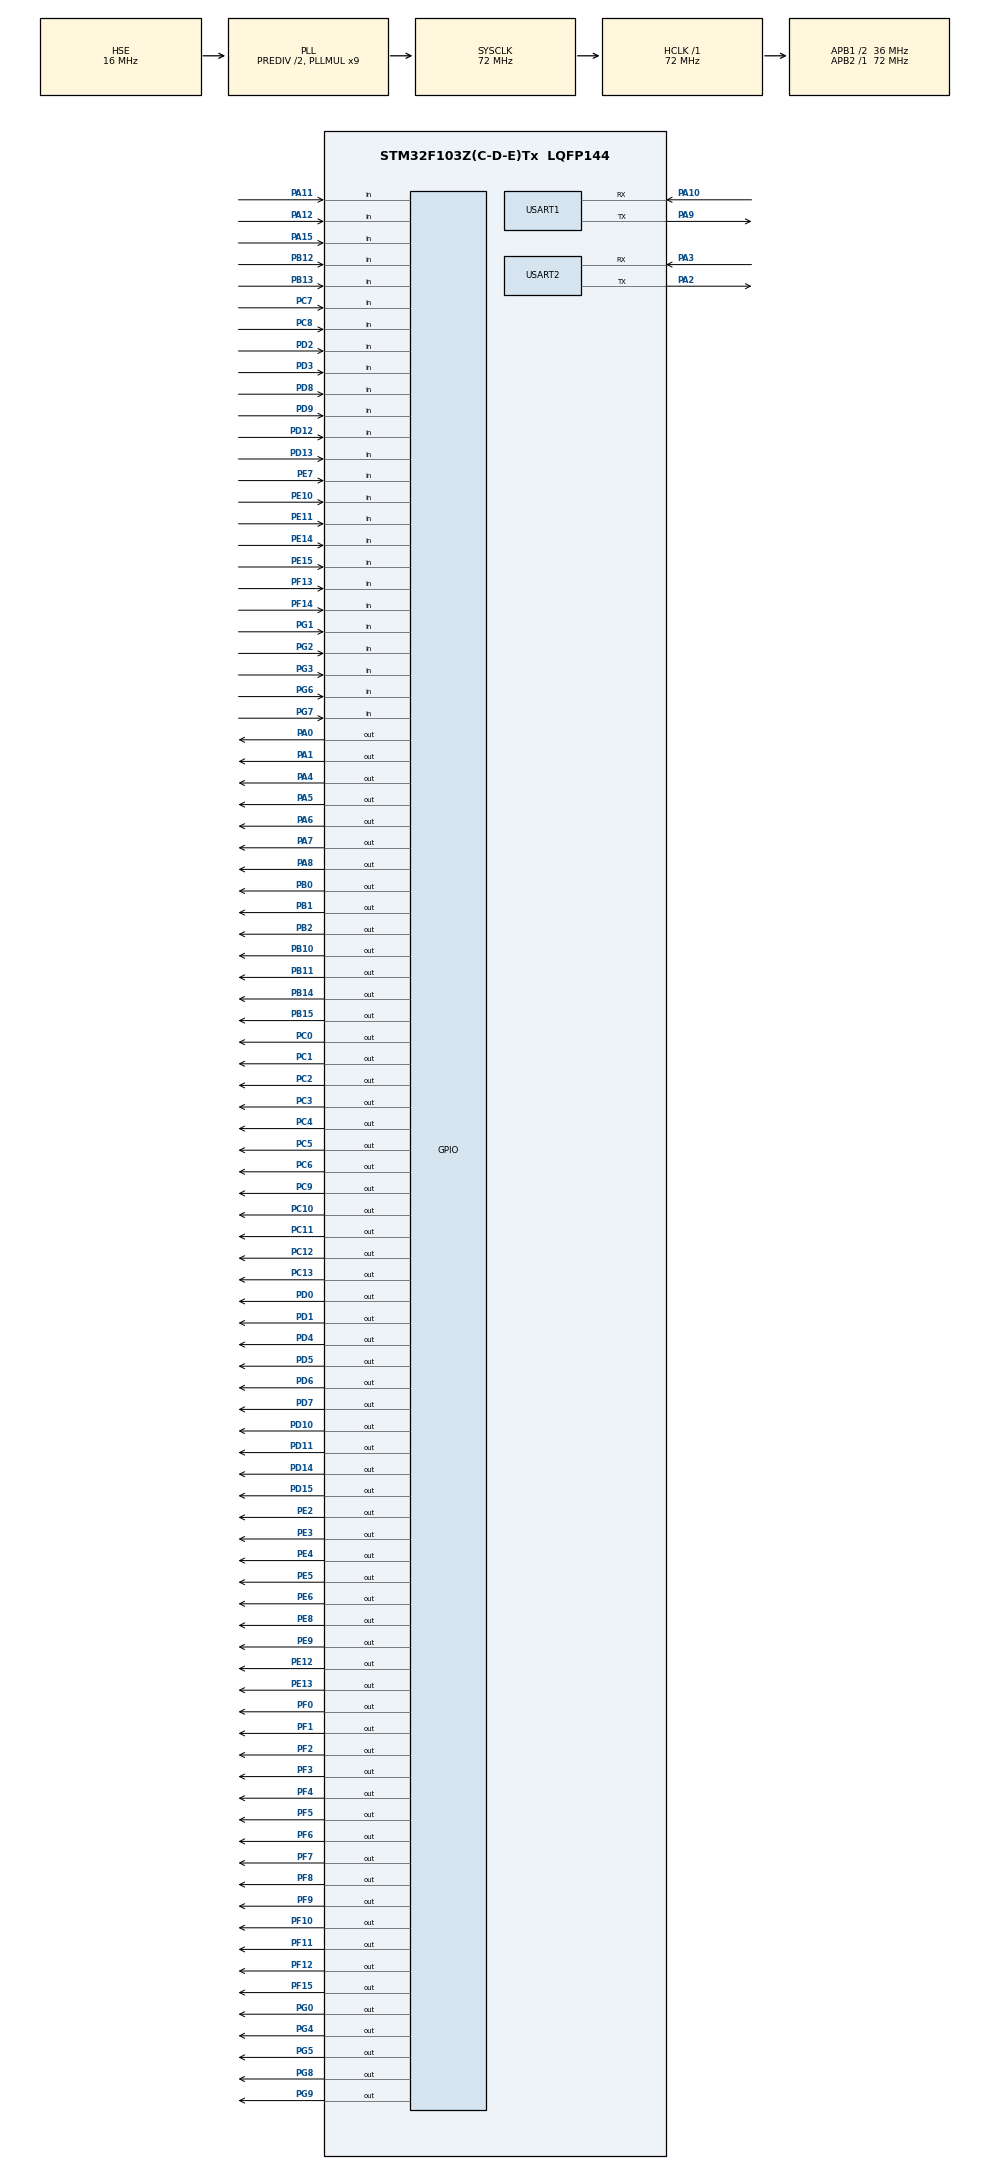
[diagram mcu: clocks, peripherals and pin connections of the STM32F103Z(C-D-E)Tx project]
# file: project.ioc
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Dma.Request0=USART2_RX
Dma.Request1=USART2_TX
Dma.Request2=USART1_TX
Dma.USART1_TX.2.Direction=DMA_MEMORY_TO_PERIPH
Dma.USART1_TX.2.Instance=DMA1_Channel4
Dma.USART1_TX.2.MemDataAlignment=DMA_MDATAALIGN_BYTE
Dma.USART1_TX.2.MemInc=DMA_MINC_ENABLE
Dma.USART1_TX.2.Mode=DMA_NORMAL
Dma.USART1_TX.2.PeriphDataAlignment=DMA_PDATAALIGN_BYTE
Dma.USART1_TX.2.PeriphInc=DMA_PINC_DISABLE
Dma.USART1_TX.2.Priority=DMA_PRIORITY_LOW
Dma.USART2_RX.0.Direction=DMA_PERIPH_TO_MEMORY
Dma.USART2_RX.0.Instance=DMA1_Channel6
Dma.USART2_RX.0.MemDataAlignment=DMA_MDATAALIGN_BYTE
Dma.USART2_RX.0.MemInc=DMA_MINC_ENABLE
Dma.USART2_RX.0.Mode=DMA_NORMAL
Dma.USART2_RX.0.PeriphDataAlignment=DMA_PDATAALIGN_BYTE
Dma.USART2_RX.0.PeriphInc=DMA_PINC_DISABLE
Dma.USART2_RX.0.Priority=DMA_PRIORITY_LOW
Dma.USART2_TX.1.Direction=DMA_MEMORY_TO_PERIPH
Dma.USART2_TX.1.Instance=DMA1_Channel7
Dma.USART2_TX.1.MemDataAlignment=DMA_MDATAALIGN_BYTE
Dma.USART2_TX.1.MemInc=DMA_MINC_ENABLE
Dma.USART2_TX.1.Mode=DMA_NORMAL
Dma.USART2_TX.1.PeriphDataAlignment=DMA_PDATAALIGN_BYTE
Dma.USART2_TX.1.PeriphInc=DMA_PINC_DISABLE
Dma.USART2_TX.1.Priority=DMA_PRIORITY_LOW
FREERTOS.Tasks01=defaultTask,0,128,StartDefaultTask,Default,NULL,Dynamic,NULL,NULL
IWDG.Prescaler=IWDG_PRESCALER_256
Mcu.Family=STM32F1
Mcu.Name=STM32F103Z(C-D-E)Tx
Mcu.Package=LQFP144
NVIC.DMA1_Channel4_IRQn=true\:5\:0\:false\:false\:true\:true\:false
NVIC.DMA1_Channel6_IRQn=true\:5\:0\:false\:false\:true\:true\:false
NVIC.DMA1_Channel7_IRQn=true\:5\:0\:false\:false\:true\:true\:false
NVIC.PriorityGroup=NVIC_PRIORITYGROUP_4
NVIC.USART1_IRQn=true\:5\:0\:false\:false\:true\:true\:true
NVIC.USART2_IRQn=true\:5\:0\:false\:false\:true\:true\:true
OSC_IN.Mode=HSE-External-Oscillator
OSC_IN.Signal=RCC_OSC_IN
OSC_OUT.Mode=HSE-External-Oscillator
OSC_OUT.Signal=RCC_OSC_OUT
PA0-WKUP.Signal=GPIO_Output
PA1.Signal=GPIO_Output
PA10.Mode=Asynchronous
PA10.Signal=USART1_RX
PA11.GPIO_PuPd=GPIO_PULLUP
PA11.Signal=GPIO_Input
PA12.GPIO_PuPd=GPIO_PULLUP
PA12.Signal=GPIO_Input
PA13.Mode=Serial_Wire
PA13.Signal=SYS_JTMS-SWDIO
PA14.Mode=Serial_Wire
PA14.Signal=SYS_JTCK-SWCLK
PA15.Signal=GPIO_Input
PA2.Mode=Asynchronous
PA2.Signal=USART2_TX
PA3.Mode=Asynchronous
PA3.Signal=USART2_RX
PA4.Signal=GPIO_Output
PA5.Signal=GPIO_Output
PA6.Signal=GPIO_Output
PA7.Signal=GPIO_Output
PA8.Signal=GPIO_Output
PA9.Mode=Asynchronous
PA9.Signal=USART1_TX
PB0.Signal=GPIO_Output
PB1.Signal=GPIO_Output
PB10.Signal=GPIO_Output
PB11.Signal=GPIO_Output
PB12.GPIO_PuPd=GPIO_PULLUP
PB12.Signal=GPIO_Input
PB13.GPIO_PuPd=GPIO_PULLUP
PB13.Signal=GPIO_Input
PB14.Signal=GPIO_Output
PB15.Signal=GPIO_Output
PB2.Signal=GPIO_Output
PC0.Signal=GPIO_Output
PC1.Signal=GPIO_Output
PC10.Signal=GPIO_Output
PC11.Signal=GPIO_Output
PC12.Signal=GPIO_Output
PC13-TAMPER-RTC.Signal=GPIO_Output
PC14-OSC32_IN.Mode=LSE-External-Oscillator
PC14-OSC32_IN.Signal=RCC_OSC32_IN
PC15-OSC32_OUT.Mode=LSE-External-Oscillator
PC15-OSC32_OUT.Signal=RCC_OSC32_OUT
PC2.Signal=GPIO_Output
PC3.Signal=GPIO_Output
PC4.Signal=GPIO_Output
PC5.Signal=GPIO_Output
PC6.Signal=GPIO_Output
PC7.GPIO_PuPd=GPIO_PULLUP
PC7.Signal=GPIO_Input
PC8.GPIO_PuPd=GPIO_PULLUP
PC8.Signal=GPIO_Input
PC9.Signal=GPIO_Output
PD0.Signal=GPIO_Output
PD1.Signal=GPIO_Output
PD10.Signal=GPIO_Output
PD11.Signal=GPIO_Output
PD12.GPIO_PuPd=GPIO_PULLUP
PD12.Signal=GPIO_Input
PD13.GPIO_PuPd=GPIO_PULLUP
PD13.Signal=GPIO_Input
PD14.Signal=GPIO_Output
PD15.Signal=GPIO_Output
PD2.GPIO_PuPd=GPIO_PULLUP
PD2.Signal=GPIO_Input
PD3.GPIO_PuPd=GPIO_NOPULL
PD3.Signal=GPIO_Input
PD4.Signal=GPIO_Output
PD5.Signal=GPIO_Output
PD6.Signal=GPIO_Output
PD7.Signal=GPIO_Output
PD8.GPIO_PuPd=GPIO_PULLUP
PD8.Signal=GPIO_Input
PD9.GPIO_PuPd=GPIO_PULLUP
PD9.Signal=GPIO_Input
PE10.GPIO_PuPd=GPIO_PULLUP
PE10.Signal=GPIO_Input
PE11.GPIO_PuPd=GPIO_PULLUP
PE11.Signal=GPIO_Input
PE12.Signal=GPIO_Output
PE13.Signal=GPIO_Output
PE14.GPIO_PuPd=GPIO_PULLUP
PE14.Signal=GPIO_Input
PE15.GPIO_PuPd=GPIO_PULLUP
PE15.Signal=GPIO_Input
PE2.Signal=GPIO_Output
PE3.Signal=GPIO_Output
PE4.Signal=GPIO_Output
PE5.Signal=GPIO_Output
PE6.Signal=GPIO_Output
PE7.GPIO_PuPd=GPIO_PULLUP
PE7.Signal=GPIO_Input
PE8.Signal=GPIO_Output
PE9.Signal=GPIO_Output
PF0.Signal=GPIO_Output
PF1.Signal=GPIO_Output
PF10.Signal=GPIO_Output
PF11.Signal=GPIO_Output
PF12.Signal=GPIO_Output
PF13.GPIO_PuPd=GPIO_PULLUP
PF13.Signal=GPIO_Input
PF14.GPIO_PuPd=GPIO_PULLUP
PF14.Signal=GPIO_Input
PF15.Signal=GPIO_Output
PF2.Signal=GPIO_Output
PF3.Signal=GPIO_Output
PF4.Signal=GPIO_Output
PF5.Signal=GPIO_Output
PF6.Signal=GPIO_Output
PF7.Signal=GPIO_Output
PF8.Signal=GPIO_Output
PF9.Signal=GPIO_Output
PG0.Signal=GPIO_Output
PG1.GPIO_PuPd=GPIO_PULLUP
PG1.Signal=GPIO_Input
PG2.GPIO_PuPd=GPIO_PULLUP
PG2.Signal=GPIO_Input
PG3.GPIO_PuPd=GPIO_PULLUP
PG3.Signal=GPIO_Input
PG4.Signal=GPIO_Output
PG5.Signal=GPIO_Output
PG6.GPIO_PuPd=GPIO_PULLUP
PG6.Signal=GPIO_Input
PG7.GPIO_PuPd=GPIO_PULLUP
PG7.Signal=GPIO_Input
PG8.Signal=GPIO_Output
PG9.Signal=GPIO_Output
ProjectManager.HeapSize=0x200
ProjectManager.StackSize=0x400
ProjectManager.TargetToolchain=EWARM V8
RCC.AHBFreq_Value=72000000
RCC.APB1CLKDivider=RCC_HCLK_DIV2
RCC.APB1Freq_Value=36000000
RCC.APB1TimFreq_Value=72000000
RCC.APB2Freq_Value=72000000
RCC.APB2TimFreq_Value=72000000
RCC.HCLKFreq_Value=72000000
RCC.HSEDivPLL=RCC_HSE_PREDIV_DIV2
RCC.HSE_VALUE=16000000
RCC.PLLMUL=RCC_PLL_MUL9
RCC.PLLSourceVirtual=RCC_PLLSOURCE_HSE
RCC.RTCClockSelection=RCC_RTCCLKSOURCE_LSE
RCC.SYSCLKFreq_VALUE=72000000
RCC.SYSCLKSource=RCC_SYSCLKSOURCE_PLLCLK
RCC.USBFreq_Value=72000000
USART1.VirtualMode=VM_ASYNC
USART2.VirtualMode=VM_ASYNC
VP_FREERTOS_VS_ENABLE.Mode=Enabled
VP_IWDG_VS_IWDG.Mode=IWDG_Activate
board=custom

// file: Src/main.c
/**
  ******************************************************************************
  * @file           : main.c
  * @brief          : Main program body
  ******************************************************************************
  * This notice applies to any and all portions of this file
  * that are not between comment pairs USER CODE BEGIN and
  * USER CODE END. Other portions of this file, whether
  * inserted by the user or by software development tools
  * are owned by their respective copyright owners.
  *
  * Copyright (c) 2019 STMicroelectronics International N.V.
  * All rights reserved.
  *
  * Redistribution and use in source and binary forms, with or without
  * modification, are permitted, provided that the following conditions are met:
  *
  * 1. Redistribution of source code must retain the above copyright notice,
  *    this list of conditions and the following disclaimer.
  * 2. Redistributions in binary form must reproduce the above copyright notice,
  *    this list of conditions and the following disclaimer in the documentation
  *    and/or other materials provided with the distribution.
  * 3. Neither the name of STMicroelectronics nor the names of other
  *    contributors to this software may be used to endorse or promote products
  *    derived from this software without specific written permission.
  * 4. This software, including modifications and/or derivative works of this
  *    software, must execute solely and exclusively on microcontroller or
  *    microprocessor devices manufactured by or for STMicroelectronics.
  * 5. Redistribution and use of this software other than as permitted under
  *    this license is void and will automatically terminate your rights under
  *    this license.
  *
  * THIS SOFTWARE IS PROVIDED BY STMICROELECTRONICS AND CONTRIBUTORS "AS IS"
  * AND ANY EXPRESS, IMPLIED OR STATUTORY WARRANTIES, INCLUDING, BUT NOT
  * LIMITED TO, THE IMPLIED WARRANTIES OF MERCHANTABILITY, FITNESS FOR A
  * PARTICULAR PURPOSE AND NON-INFRINGEMENT OF THIRD PARTY INTELLECTUAL PROPERTY
  * RIGHTS ARE DISCLAIMED TO THE FULLEST EXTENT PERMITTED BY LAW. IN NO EVENT
  * SHALL STMICROELECTRONICS OR CONTRIBUTORS BE LIABLE FOR ANY DIRECT, INDIRECT,
  * INCIDENTAL, SPECIAL, EXEMPLARY, OR CONSEQUENTIAL DAMAGES (INCLUDING, BUT NOT
  * LIMITED TO, PROCUREMENT OF SUBSTITUTE GOODS OR SERVICES; LOSS OF USE, DATA,
  * OR PROFITS; OR BUSINESS INTERRUPTION) HOWEVER CAUSED AND ON ANY THEORY OF
  * LIABILITY, WHETHER IN CONTRACT, STRICT LIABILITY, OR TORT (INCLUDING
  * NEGLIGENCE OR OTHERWISE) ARISING IN ANY WAY OUT OF THE USE OF THIS SOFTWARE,
  * EVEN IF ADVISED OF THE POSSIBILITY OF SUCH DAMAGE.
  *
  ******************************************************************************
  */
#include "main.h"
#include "stm32f1xx_hal.h"
#include "cmsis_os.h"

/* USER CODE BEGIN Includes */
#include "user_comm.h"
/* USER CODE END Includes */

IWDG_HandleTypeDef hiwdg;

UART_HandleTypeDef huart1;
UART_HandleTypeDef huart2;
DMA_HandleTypeDef hdma_usart1_tx;
DMA_HandleTypeDef hdma_usart2_rx;
DMA_HandleTypeDef hdma_usart2_tx;

osThreadId defaultTaskHandle;

/* USER CODE BEGIN PV */
/* Private variables ---------------------------------------------------------*/

/* USER CODE END PV */

void SystemClock_Config(void);
static void MX_GPIO_Init(void);
static void MX_DMA_Init(void);
static void MX_USART1_UART_Init(void);
static void MX_USART2_UART_Init(void);
static void MX_IWDG_Init(void);
void StartDefaultTask(void const * argument);

/* USER CODE BEGIN PFP */
/* Private function prototypes -----------------------------------------------*/

/* USER CODE END PFP */

/* USER CODE BEGIN 0 */
#ifdef __GNUC__
  /* With GCC/RAISONANCE, small printf (option LD Linker->Libraries->Small printf
     set to 'Yes') calls __io_putchar() */
  #define PUTCHAR_PROTOTYPE int __io_putchar(int ch)
#else
  #define PUTCHAR_PROTOTYPE int fputc(int ch, FILE *f)
#endif /* __GNUC__ */
/**
  * @brief  Retargets the C library printf function to the USART.
  * @param  None
  * @retval None
  */
PUTCHAR_PROTOTYPE
{
  /* Place your implementation of fputc here */
  /* e.g. write a character to the EVAL_COM1 and Loop until the end of transmission */
  HAL_UART_Transmit(&huart1, (uint8_t *)&ch, 1, 0xFFFF);

  return ch;
}

/* USER CODE END 0 */

int main(void)
{

  /* MCU Configuration----------------------------------------------------------*/

  /* Reset of all peripherals, Initializes the Flash interface and the Systick. */
  HAL_Init();

  /* Configure the system clock */
  SystemClock_Config();

  /* Initialize all configured peripherals */
  MX_GPIO_Init();
  MX_DMA_Init();
  MX_USART1_UART_Init();
  MX_USART2_UART_Init();
  MX_IWDG_Init();
  /* USER CODE BEGIN 2 */
  printf("main init printf ok \n");

  /* USER CODE END 2 */

  /* Create the thread(s) */
  /* definition and creation of defaultTask */
  osThreadDef(defaultTask, StartDefaultTask, osPriorityNormal, 0, 128);
  defaultTaskHandle = osThreadCreate(osThread(defaultTask), NULL);

  /* Start scheduler */
  osKernelStart();

  /* We should never get here as control is now taken by the scheduler */

  /* Infinite loop */
  while (1)
  {

  }

}

void SystemClock_Config(void)
{

  RCC_OscInitTypeDef RCC_OscInitStruct;
  RCC_ClkInitTypeDef RCC_ClkInitStruct;

    /**Initializes the CPU, AHB and APB busses clocks
    */
  RCC_OscInitStruct.OscillatorType = RCC_OSCILLATORTYPE_LSI|RCC_OSCILLATORTYPE_HSE;
  RCC_OscInitStruct.HSEState = RCC_HSE_ON;
  RCC_OscInitStruct.HSEPredivValue = RCC_HSE_PREDIV_DIV2;
  RCC_OscInitStruct.HSIState = RCC_HSI_ON;
  RCC_OscInitStruct.LSIState = RCC_LSI_ON;
  RCC_OscInitStruct.PLL.PLLState = RCC_PLL_ON;
  RCC_OscInitStruct.PLL.PLLSource = RCC_PLLSOURCE_HSE;
  RCC_OscInitStruct.PLL.PLLMUL = RCC_PLL_MUL9;
  if (HAL_RCC_OscConfig(&RCC_OscInitStruct) != HAL_OK)
  {
    _Error_Handler(__FILE__, __LINE__);
  }

    /**Initializes the CPU, AHB and APB busses clocks
    */
  RCC_ClkInitStruct.ClockType = RCC_CLOCKTYPE_HCLK|RCC_CLOCKTYPE_SYSCLK
                              |RCC_CLOCKTYPE_PCLK1|RCC_CLOCKTYPE_PCLK2;
  RCC_ClkInitStruct.SYSCLKSource = RCC_SYSCLKSOURCE_PLLCLK;
  RCC_ClkInitStruct.AHBCLKDivider = RCC_SYSCLK_DIV1;
  RCC_ClkInitStruct.APB1CLKDivider = RCC_HCLK_DIV2;
  RCC_ClkInitStruct.APB2CLKDivider = RCC_HCLK_DIV1;

  if (HAL_RCC_ClockConfig(&RCC_ClkInitStruct, FLASH_LATENCY_2) != HAL_OK)
  {
    _Error_Handler(__FILE__, __LINE__);
  }

    /**Configure the Systick interrupt time
    */
  HAL_SYSTICK_Config(HAL_RCC_GetHCLKFreq()/1000);

    /**Configure the Systick
    */
  HAL_SYSTICK_CLKSourceConfig(SYSTICK_CLKSOURCE_HCLK);

  /* SysTick_IRQn interrupt configuration */
  HAL_NVIC_SetPriority(SysTick_IRQn, 15, 0);
}

/* IWDG init function */
static void MX_IWDG_Init(void)
{

  hiwdg.Instance = IWDG;
  hiwdg.Init.Prescaler = IWDG_PRESCALER_256;
  hiwdg.Init.Reload = 4095;
  if (HAL_IWDG_Init(&hiwdg) != HAL_OK)
  {
    _Error_Handler(__FILE__, __LINE__);
  }

}

/* USART1 init function */
static void MX_USART1_UART_Init(void)
{

  huart1.Instance = USART1;
  huart1.Init.BaudRate = 115200;
  huart1.Init.WordLength = UART_WORDLENGTH_8B;
  huart1.Init.StopBits = UART_STOPBITS_1;
  huart1.Init.Parity = UART_PARITY_NONE;
  huart1.Init.Mode = UART_MODE_TX_RX;
  huart1.Init.HwFlowCtl = UART_HWCONTROL_NONE;
  huart1.Init.OverSampling = UART_OVERSAMPLING_16;
  if (HAL_UART_Init(&huart1) != HAL_OK)
  {
    _Error_Handler(__FILE__, __LINE__);
  }

}

/* USART2 init function */
static void MX_USART2_UART_Init(void)
{

  huart2.Instance = USART2;
  huart2.Init.BaudRate = 115200;
  huart2.Init.WordLength = UART_WORDLENGTH_8B;
  huart2.Init.StopBits = UART_STOPBITS_1;
  huart2.Init.Parity = UART_PARITY_NONE;
  huart2.Init.Mode = UART_MODE_TX_RX;
  huart2.Init.HwFlowCtl = UART_HWCONTROL_NONE;
  huart2.Init.OverSampling = UART_OVERSAMPLING_16;
  if (HAL_UART_Init(&huart2) != HAL_OK)
  {
    _Error_Handler(__FILE__, __LINE__);
  }

}

static void MX_DMA_Init(void)
{
  /* DMA controller clock enable */
  __HAL_RCC_DMA1_CLK_ENABLE();

  /* DMA interrupt init */
  /* DMA1_Channel4_IRQn interrupt configuration */
  HAL_NVIC_SetPriority(DMA1_Channel4_IRQn, 5, 0);
  HAL_NVIC_EnableIRQ(DMA1_Channel4_IRQn);
  /* DMA1_Channel6_IRQn interrupt configuration */
  HAL_NVIC_SetPriority(DMA1_Channel6_IRQn, 5, 0);
  HAL_NVIC_EnableIRQ(DMA1_Channel6_IRQn);
  /* DMA1_Channel7_IRQn interrupt configuration */
  HAL_NVIC_SetPriority(DMA1_Channel7_IRQn, 5, 0);
  HAL_NVIC_EnableIRQ(DMA1_Channel7_IRQn);

}

/** Configure pins as
        * Analog
        * Input
        * Output
        * EVENT_OUT
        * EXTI
*/
static void MX_GPIO_Init(void)
{

  GPIO_InitTypeDef GPIO_InitStruct;

  /* GPIO Ports Clock Enable */
  __HAL_RCC_GPIOE_CLK_ENABLE();
  __HAL_RCC_GPIOC_CLK_ENABLE();
  __HAL_RCC_GPIOF_CLK_ENABLE();
  __HAL_RCC_GPIOA_CLK_ENABLE();
  __HAL_RCC_GPIOB_CLK_ENABLE();
  __HAL_RCC_GPIOG_CLK_ENABLE();
  __HAL_RCC_GPIOD_CLK_ENABLE();

  /*Configure GPIO pin Output Level */
  HAL_GPIO_WritePin(GPIOE, GPIO_PIN_2|GPIO_PIN_3|GPIO_PIN_4|GPIO_PIN_5
                          |GPIO_PIN_6|GPIO_PIN_8|GPIO_PIN_9|GPIO_PIN_12
                          |GPIO_PIN_13, GPIO_PIN_RESET);

  /*Configure GPIO pin Output Level */
  HAL_GPIO_WritePin(GPIOC, GPIO_PIN_13|GPIO_PIN_0|GPIO_PIN_1|GPIO_PIN_2
                          |GPIO_PIN_3|GPIO_PIN_4|GPIO_PIN_5|GPIO_PIN_6
                          |GPIO_PIN_9|GPIO_PIN_10|GPIO_PIN_11|GPIO_PIN_12, GPIO_PIN_RESET);

  /*Configure GPIO pin Output Level */
  HAL_GPIO_WritePin(GPIOF, GPIO_PIN_0|GPIO_PIN_1|GPIO_PIN_2|GPIO_PIN_3
                          |GPIO_PIN_4|GPIO_PIN_5|GPIO_PIN_6|GPIO_PIN_7
                          |GPIO_PIN_8|GPIO_PIN_9|GPIO_PIN_10|GPIO_PIN_11
                          |GPIO_PIN_12|GPIO_PIN_15, GPIO_PIN_RESET);

  /*Configure GPIO pin Output Level */
  HAL_GPIO_WritePin(GPIOA, GPIO_PIN_0|GPIO_PIN_1|GPIO_PIN_4|GPIO_PIN_5
                          |GPIO_PIN_6|GPIO_PIN_7|GPIO_PIN_8, GPIO_PIN_RESET);

  /*Configure GPIO pin Output Level */
  HAL_GPIO_WritePin(GPIOB, GPIO_PIN_0|GPIO_PIN_1|GPIO_PIN_2|GPIO_PIN_10
                          |GPIO_PIN_11|GPIO_PIN_14|GPIO_PIN_15, GPIO_PIN_RESET);

  /*Configure GPIO pin Output Level */
  HAL_GPIO_WritePin(GPIOG, GPIO_PIN_0|GPIO_PIN_4|GPIO_PIN_5|GPIO_PIN_8
                          |GPIO_PIN_9, GPIO_PIN_RESET);

  /*Configure GPIO pin Output Level */
  HAL_GPIO_WritePin(GPIOD, GPIO_PIN_10|GPIO_PIN_11|GPIO_PIN_14|GPIO_PIN_15
                          |GPIO_PIN_0|GPIO_PIN_1|GPIO_PIN_4|GPIO_PIN_5
                          |GPIO_PIN_6|GPIO_PIN_7, GPIO_PIN_RESET);

  /*Configure GPIO pins : PE2 PE3 PE4 PE5
                           PE6 PE8 PE9 PE12
                           PE13 */
  GPIO_InitStruct.Pin = GPIO_PIN_2|GPIO_PIN_3|GPIO_PIN_4|GPIO_PIN_5
                          |GPIO_PIN_6|GPIO_PIN_8|GPIO_PIN_9|GPIO_PIN_12
                          |GPIO_PIN_13;
  GPIO_InitStruct.Mode = GPIO_MODE_OUTPUT_PP;
  GPIO_InitStruct.Pull = GPIO_NOPULL;
  GPIO_InitStruct.Speed = GPIO_SPEED_FREQ_LOW;
  HAL_GPIO_Init(GPIOE, &GPIO_InitStruct);

  /*Configure GPIO pins : PC13 PC0 PC1 PC2
                           PC3 PC4 PC5 PC6
                           PC9 PC10 PC11 PC12 */
  GPIO_InitStruct.Pin = GPIO_PIN_13|GPIO_PIN_0|GPIO_PIN_1|GPIO_PIN_2
                          |GPIO_PIN_3|GPIO_PIN_4|GPIO_PIN_5|GPIO_PIN_6
                          |GPIO_PIN_9|GPIO_PIN_10|GPIO_PIN_11|GPIO_PIN_12;
  GPIO_InitStruct.Mode = GPIO_MODE_OUTPUT_PP;
  GPIO_InitStruct.Pull = GPIO_NOPULL;
  GPIO_InitStruct.Speed = GPIO_SPEED_FREQ_LOW;
  HAL_GPIO_Init(GPIOC, &GPIO_InitStruct);

  /*Configure GPIO pins : PF0 PF1 PF2 PF3
                           PF4 PF5 PF6 PF7
                           PF8 PF9 PF10 PF11
                           PF12 PF15 */
  GPIO_InitStruct.Pin = GPIO_PIN_0|GPIO_PIN_1|GPIO_PIN_2|GPIO_PIN_3
                          |GPIO_PIN_4|GPIO_PIN_5|GPIO_PIN_6|GPIO_PIN_7
                          |GPIO_PIN_8|GPIO_PIN_9|GPIO_PIN_10|GPIO_PIN_11
                          |GPIO_PIN_12|GPIO_PIN_15;
  GPIO_InitStruct.Mode = GPIO_MODE_OUTPUT_PP;
  GPIO_InitStruct.Pull = GPIO_NOPULL;
  GPIO_InitStruct.Speed = GPIO_SPEED_FREQ_LOW;
  HAL_GPIO_Init(GPIOF, &GPIO_InitStruct);

  /*Configure GPIO pins : PA0 PA1 PA4 PA5
                           PA6 PA7 PA8 */
  GPIO_InitStruct.Pin = GPIO_PIN_0|GPIO_PIN_1|GPIO_PIN_4|GPIO_PIN_5
                          |GPIO_PIN_6|GPIO_PIN_7|GPIO_PIN_8;
  GPIO_InitStruct.Mode = GPIO_MODE_OUTPUT_PP;
  GPIO_InitStruct.Pull = GPIO_NOPULL;
  GPIO_InitStruct.Speed = GPIO_SPEED_FREQ_LOW;
  HAL_GPIO_Init(GPIOA, &GPIO_InitStruct);

  /*Configure GPIO pins : PB0 PB1 PB2 PB10
                           PB11 PB14 PB15 */
  GPIO_InitStruct.Pin = GPIO_PIN_0|GPIO_PIN_1|GPIO_PIN_2|GPIO_PIN_10
                          |GPIO_PIN_11|GPIO_PIN_14|GPIO_PIN_15;
  GPIO_InitStruct.Mode = GPIO_MODE_OUTPUT_PP;
  GPIO_InitStruct.Pull = GPIO_NOPULL;
  GPIO_InitStruct.Speed = GPIO_SPEED_FREQ_LOW;
  HAL_GPIO_Init(GPIOB, &GPIO_InitStruct);

  /*Configure GPIO pins : PF13 PF14 */
  GPIO_InitStruct.Pin = GPIO_PIN_13|GPIO_PIN_14;
  GPIO_InitStruct.Mode = GPIO_MODE_INPUT;
  GPIO_InitStruct.Pull = GPIO_PULLUP;
  HAL_GPIO_Init(GPIOF, &GPIO_InitStruct);

  /*Configure GPIO pins : PG0 PG4 PG5 PG8
                           PG9 */
  GPIO_InitStruct.Pin = GPIO_PIN_0|GPIO_PIN_4|GPIO_PIN_5|GPIO_PIN_8
                          |GPIO_PIN_9;
  GPIO_InitStruct.Mode = GPIO_MODE_OUTPUT_PP;
  GPIO_InitStruct.Pull = GPIO_NOPULL;
  GPIO_InitStruct.Speed = GPIO_SPEED_FREQ_LOW;
  HAL_GPIO_Init(GPIOG, &GPIO_InitStruct);

  /*Configure GPIO pins : PG1 PG2 PG3 PG6
                           PG7 */
  GPIO_InitStruct.Pin = GPIO_PIN_1|GPIO_PIN_2|GPIO_PIN_3|GPIO_PIN_6
                          |GPIO_PIN_7;
  GPIO_InitStruct.Mode = GPIO_MODE_INPUT;
  GPIO_InitStruct.Pull = GPIO_PULLUP;
  HAL_GPIO_Init(GPIOG, &GPIO_InitStruct);

  /*Configure GPIO pins : PE7 PE10 PE11 PE14
                           PE15 */
  GPIO_InitStruct.Pin = GPIO_PIN_7|GPIO_PIN_10|GPIO_PIN_11|GPIO_PIN_14
                          |GPIO_PIN_15;
  GPIO_InitStruct.Mode = GPIO_MODE_INPUT;
  GPIO_InitStruct.Pull = GPIO_PULLUP;
  HAL_GPIO_Init(GPIOE, &GPIO_InitStruct);

  /*Configure GPIO pins : PB12 PB13 */
  GPIO_InitStruct.Pin = GPIO_PIN_12|GPIO_PIN_13;
  GPIO_InitStruct.Mode = GPIO_MODE_INPUT;
  GPIO_InitStruct.Pull = GPIO_PULLUP;
  HAL_GPIO_Init(GPIOB, &GPIO_InitStruct);

  /*Configure GPIO pins : PD8 PD9 PD12 PD13
                           PD2 */
  GPIO_InitStruct.Pin = GPIO_PIN_8|GPIO_PIN_9|GPIO_PIN_12|GPIO_PIN_13
                          |GPIO_PIN_2;
  GPIO_InitStruct.Mode = GPIO_MODE_INPUT;
  GPIO_InitStruct.Pull = GPIO_PULLUP;
  HAL_GPIO_Init(GPIOD, &GPIO_InitStruct);

  /*Configure GPIO pins : PD10 PD11 PD14 PD15
                           PD0 PD1 PD4 PD5
                           PD6 PD7 */
  GPIO_InitStruct.Pin = GPIO_PIN_10|GPIO_PIN_11|GPIO_PIN_14|GPIO_PIN_15
                          |GPIO_PIN_0|GPIO_PIN_1|GPIO_PIN_4|GPIO_PIN_5
                          |GPIO_PIN_6|GPIO_PIN_7;
  GPIO_InitStruct.Mode = GPIO_MODE_OUTPUT_PP;
  GPIO_InitStruct.Pull = GPIO_NOPULL;
  GPIO_InitStruct.Speed = GPIO_SPEED_FREQ_LOW;
  HAL_GPIO_Init(GPIOD, &GPIO_InitStruct);

  /*Configure GPIO pins : PC7 PC8 */
  GPIO_InitStruct.Pin = GPIO_PIN_7|GPIO_PIN_8;
  GPIO_InitStruct.Mode = GPIO_MODE_INPUT;
  GPIO_InitStruct.Pull = GPIO_PULLUP;
  HAL_GPIO_Init(GPIOC, &GPIO_InitStruct);

  /*Configure GPIO pins : PA11 PA12 */
  GPIO_InitStruct.Pin = GPIO_PIN_11|GPIO_PIN_12;
  GPIO_InitStruct.Mode = GPIO_MODE_INPUT;
  GPIO_InitStruct.Pull = GPIO_PULLUP;
  HAL_GPIO_Init(GPIOA, &GPIO_InitStruct);

  /*Configure GPIO pin : PA15 */
  GPIO_InitStruct.Pin = GPIO_PIN_15;
  GPIO_InitStruct.Mode = GPIO_MODE_INPUT;
  GPIO_InitStruct.Pull = GPIO_NOPULL;
  HAL_GPIO_Init(GPIOA, &GPIO_InitStruct);

  /*Configure GPIO pin : PD3 */
  GPIO_InitStruct.Pin = GPIO_PIN_3;
  GPIO_InitStruct.Mode = GPIO_MODE_INPUT;
  GPIO_InitStruct.Pull = GPIO_NOPULL;
  HAL_GPIO_Init(GPIOD, &GPIO_InitStruct);

}

void StartDefaultTask(void const * argument)
{

  /* USER CODE BEGIN 5 */
  TWDT_DEF(startTask, 10000);
  TWDT_ADD(startTask);
  TWDT_CLEAR(startTask);
  TWDT_ONOFF(startTask,1);

  UART_PortConfig(1, &huart1, UART1_RECEVIE_BUFFER_SIZE);
  UART_PortConfig(2, &huart2, UART2_RECEVIE_BUFFER_SIZE);
  System_Init();

  CMD_Init();
  Motor_Cmd_Init();
  BarcodeScan_Cmd_Init();
  Return_Lock_Cmd_Init();

  DBG_LOG("System Start!");

  /* Infinite loop */
  for(;;)
  {
    osDelay(2);
    CMD_UART_Read_Poll();
    UART_Refresh_Poll();
    TWDT_CLEAR(startTask);
  }
  /* USER CODE END 5 */
}

void _Error_Handler(char *file, int line)
{
  while(1)
  {
  }
}

/************************ (C) COPYRIGHT STMicroelectronics *****END OF FILE****/

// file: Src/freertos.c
/* USER CODE BEGIN Header */
/**
  ******************************************************************************
  * File Name          : freertos.c
  * Description        : Code for freertos applications
  ******************************************************************************
  * This notice applies to any and all portions of this file
  * that are not between comment pairs USER CODE BEGIN and
  * USER CODE END. Other portions of this file, whether
  * inserted by the user or by software development tools
  * are owned by their respective copyright owners.
  *
  * Copyright (c) 2018 STMicroelectronics International N.V.
  * All rights reserved.
  *
  * Redistribution and use in source and binary forms, with or without
  * modification, are permitted, provided that the following conditions are met:
  *
  * 1. Redistribution of source code must retain the above copyright notice,
  *    this list of conditions and the following disclaimer.
  * 2. Redistributions in binary form must reproduce the above copyright notice,
  *    this list of conditions and the following disclaimer in the documentation
  *    and/or other materials provided with the distribution.
  * 3. Neither the name of STMicroelectronics nor the names of other
  *    contributors to this software may be used to endorse or promote products
  *    derived from this software without specific written permission.
  * 4. This software, including modifications and/or derivative works of this
  *    software, must execute solely and exclusively on microcontroller or
  *    microprocessor devices manufactured by or for STMicroelectronics.
  * 5. Redistribution and use of this software other than as permitted under
  *    this license is void and will automatically terminate your rights under
  *    this license.
  *
  * THIS SOFTWARE IS PROVIDED BY STMICROELECTRONICS AND CONTRIBUTORS "AS IS"
  * AND ANY EXPRESS, IMPLIED OR STATUTORY WARRANTIES, INCLUDING, BUT NOT
  * LIMITED TO, THE IMPLIED WARRANTIES OF MERCHANTABILITY, FITNESS FOR A
  * PARTICULAR PURPOSE AND NON-INFRINGEMENT OF THIRD PARTY INTELLECTUAL PROPERTY
  * RIGHTS ARE DISCLAIMED TO THE FULLEST EXTENT PERMITTED BY LAW. IN NO EVENT
  * SHALL STMICROELECTRONICS OR CONTRIBUTORS BE LIABLE FOR ANY DIRECT, INDIRECT,
  * INCIDENTAL, SPECIAL, EXEMPLARY, OR CONSEQUENTIAL DAMAGES (INCLUDING, BUT NOT
  * LIMITED TO, PROCUREMENT OF SUBSTITUTE GOODS OR SERVICES; LOSS OF USE, DATA,
  * OR PROFITS; OR BUSINESS INTERRUPTION) HOWEVER CAUSED AND ON ANY THEORY OF
  * LIABILITY, WHETHER IN CONTRACT, STRICT LIABILITY, OR TORT (INCLUDING
  * NEGLIGENCE OR OTHERWISE) ARISING IN ANY WAY OUT OF THE USE OF THIS SOFTWARE,
  * EVEN IF ADVISED OF THE POSSIBILITY OF SUCH DAMAGE.
  *
  ******************************************************************************
  */
/* USER CODE END Header */

#include "FreeRTOS.h"
#include "task.h"
#include "main.h"

/* USER CODE BEGIN Includes */
#include "user_comm.h"
/* USER CODE END Includes */

/* USER CODE BEGIN Variables */
extern IWDG_HandleTypeDef hiwdg;
/* USER CODE END Variables */

/* USER CODE BEGIN FunctionPrototypes */
void vApplicationIdleHook(void);
void vApplicationTickHook(void);
void vApplicationStackOverflowHook(xTaskHandle xTask, signed char *pcTaskName);
void vApplicationMallocFailedHook(void);
/* USER CODE END FunctionPrototypes */

/* USER CODE BEGIN Application */
   /* USER CODE BEGIN 2 */
void vApplicationIdleHook(void)
{
    /* vApplicationIdleHook() will only be called if configUSE_IDLE_HOOK is set
    to 1 in FreeRTOSConfig.h. It will be called on each iteration of the idle
    task. It is essential that code added to this hook function never attempts
    to block in any way (for example, call xQueueReceive() with a block time
    specified, or call vTaskDelay()). If the application makes use of the
    vTaskDelete() API function (as this demo application does) then it is also
    important that vApplicationIdleHook() is permitted to return to its calling
    function, because it is the responsibility of the idle task to clean up
    memory allocated by the kernel to any task that has since been deleted. */

    char *name = NULL;

    name = TaskWDG_IsUpper();
    if (name == NULL) {
        HAL_IWDG_Refresh(&hiwdg);
    } else {
        THROW(name);
        printf(" task watchdog overflow, system will reset.\r\n");
        HAL_Delay(1000);
    }
}
/* USER CODE END 2 */

/* USER CODE BEGIN 3 */
void vApplicationTickHook(void)
{
    /* This function will be called by each tick interrupt if
    configUSE_TICK_HOOK is set to 1 in FreeRTOSConfig.h. User code can be
    added here, but the tick hook is called from an interrupt context, so
    code must not attempt to block, and only the interrupt safe FreeRTOS API
    functions can be used (those that end in FromISR()). */
    char *name = NULL;
    name = TaskWDG_Tick();
    if (name != NULL) {
        THROW(name);
        printf(" task watchdog overflow, system will reset.\r\n");
     //   HAL_IWDG_Refresh(&hiwdg);
    }
}
/* USER CODE END 3 */

/* USER CODE BEGIN 4 */
__weak void vApplicationStackOverflowHook(xTaskHandle xTask, signed char *pcTaskName)
{
    /* Run time stack overflow checking is performed if
    configCHECK_FOR_STACK_OVERFLOW is defined to 1 or 2. This hook function is
    called if a stack overflow is detected. */

    THROW((char*)pcTaskName);
    THROW(" Task Overflow.!!\r\n");
    HAL_Delay(1000);
}
/* USER CODE END 4 */

/* USER CODE BEGIN 5 */
void vApplicationMallocFailedHook(void)
{
    /* vApplicationMallocFailedHook() will only be called if
    configUSE_MALLOC_FAILED_HOOK is set to 1 in FreeRTOSConfig.h. It is a hook
    function that will get called if a call to pvPortMalloc() fails.
    pvPortMalloc() is called internally by the kernel whenever a task, queue,
    timer or semaphore is created. It is also called by various parts of the
    demo application. If heap_1.c or heap_2.c are used, then the size of the
    heap available to pvPortMalloc() is defined by configTOTAL_HEAP_SIZE in
    FreeRTOSConfig.h, and the xPortGetFreeHeapSize() API function can be used
    to query the size of free heap space that remains (although it does not
    provide information on how the remaining heap might be fragmented). */

    static uint16_t failindex = 0;

    failindex++;
    while (failindex > 10) {
        THROW("Memory malloc failed!!\r\n");
        HAL_Delay(1000);
    }
}
/* USER CODE END 5 */
/* USER CODE END Application */

/************************ (C) COPYRIGHT STMicroelectronics *****END OF FILE****/
